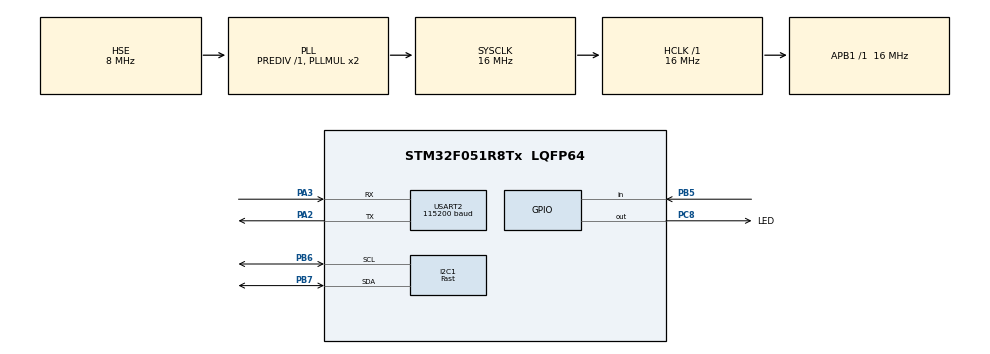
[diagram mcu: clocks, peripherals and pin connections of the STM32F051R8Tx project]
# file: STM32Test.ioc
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I2C1.I2C_Speed_Mode=I2C_Fast
I2C1.Timing=0x0000020B
Mcu.Family=STM32F0
Mcu.Name=STM32F051R8Tx
Mcu.Package=LQFP64
NVIC.I2C1_IRQn=true\:0\:0\:false\:false\:true\:true\:true\:true
NVIC.RCC_IRQn=true\:0\:0\:false\:false\:true\:true\:false\:true
NVIC.TIM1_BRK_UP_TRG_COM_IRQn=true\:0\:0\:false\:false\:true\:true\:true\:true
NVIC.USART2_IRQn=true\:0\:0\:false\:false\:true\:true\:true\:true
PA2.Mode=Asynchronous
PA2.Signal=USART2_TX
PA3.Mode=Asynchronous
PA3.Signal=USART2_RX
PB5.Signal=GPIO_Input
PB6.Mode=I2C
PB6.Signal=I2C1_SCL
PB7.Mode=I2C
PB7.Signal=I2C1_SDA
PC8.GPIO_Label=LED
PC8.Signal=GPIO_Output
PF0-OSC_IN.Mode=HSE-External-Oscillator
PF0-OSC_IN.Signal=RCC_OSC_IN
PF1-OSC_OUT.Mode=HSE-External-Oscillator
PF1-OSC_OUT.Signal=RCC_OSC_OUT
ProjectManager.HeapSize=0x200
ProjectManager.StackSize=0x400
ProjectManager.TargetToolchain=Makefile
RCC.AHBFreq_Value=16000000
RCC.APB1Freq_Value=16000000
RCC.APB1TimFreq_Value=16000000
RCC.HCLKFreq_Value=16000000
RCC.PLLSourceVirtual=RCC_PLLSOURCE_HSE
RCC.SYSCLKFreq_VALUE=16000000
RCC.SYSCLKSource=RCC_SYSCLKSOURCE_PLLCLK
TIM1.Period=25000
TIM1.Prescaler=159
USART2.BaudRate=115200
USART2.VirtualMode-Asynchronous=VM_ASYNC
VP_TIM1_VS_ClockSourceINT.Mode=Internal
board=custom

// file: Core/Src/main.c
/* USER CODE BEGIN Header */
/**
  ******************************************************************************
  * @file           : main.c
  * @brief          : Main program body
  ******************************************************************************
  * @attention
  *
  * Copyright (c) 2024 STMicroelectronics.
  * All rights reserved.
  *
  * This software is licensed under terms that can be found in the LICENSE file
  * in the root directory of this software component.
  * If no LICENSE file comes with this software, it is provided AS-IS.
  *
  ******************************************************************************
  */
/* USER CODE END Header */
#include "main.h"
#include "i2c.h"
#include "tim.h"
#include "usart.h"
#include "gpio.h"

/* USER CODE BEGIN Includes */

#include "MPU6050.h"

/* USER CODE END Includes */

/* USER CODE BEGIN PTD */

int _write(int file, uint8_t* p, int len)
{
	if(HAL_UART_Transmit(&huart2, p, len, len) == HAL_OK )
	{
		return len;
	}
	return 0;
}

/* USER CODE END PTD */

void SystemClock_Config(void);

/* USER CODE BEGIN 0 */

void HAL_TIM_PeriodElapsedCallback(TIM_HandleTypeDef *htim)
{
      //HAL_GPIO_WritePin(LED_GPIO_Port, LED_Pin, GPIO_PIN_SET);
      MPU6050_ProcessData(&MPU6050);
      printf("acc_x_raw: %d, acc_y_raw: %d, acc_z_raw: %d, gyro_x_raw: %d, gyro_y_raw: %d, gyro_z_raw: %d \n\r", MPU6050.acc_x_raw, MPU6050.acc_y_raw, MPU6050.acc_z_raw,MPU6050.gyro_x_raw, MPU6050.gyro_y_raw, MPU6050.gyro_z_raw );

}

/* USER CODE END 0 */

int main(void)
{

  /* MCU Configuration--------------------------------------------------------*/

  /* Reset of all peripherals, Initializes the Flash interface and the Systick. */
  HAL_Init();

  /* Configure the system clock */
  SystemClock_Config();

  /* Initialize all configured peripherals */
  MX_GPIO_Init();
  MX_I2C1_Init();
  MX_USART2_UART_Init();
  MX_TIM1_Init();
  /* USER CODE BEGIN 2 */
  MPU6050_Initialization();

  HAL_TIM_Base_Start_IT(&htim1);

  /* USER CODE END 2 */

  /* Infinite loop */
  while (1)
  {

  }
}

void SystemClock_Config(void)
{
  RCC_OscInitTypeDef RCC_OscInitStruct = {0};
  RCC_ClkInitTypeDef RCC_ClkInitStruct = {0};
  RCC_PeriphCLKInitTypeDef PeriphClkInit = {0};

  /** Initializes the RCC Oscillators according to the specified parameters
  * in the RCC_OscInitTypeDef structure.
  */
  RCC_OscInitStruct.OscillatorType = RCC_OSCILLATORTYPE_HSI|RCC_OSCILLATORTYPE_HSE;
  RCC_OscInitStruct.HSEState = RCC_HSE_ON;
  RCC_OscInitStruct.HSIState = RCC_HSI_ON;
  RCC_OscInitStruct.HSICalibrationValue = RCC_HSICALIBRATION_DEFAULT;
  RCC_OscInitStruct.PLL.PLLState = RCC_PLL_ON;
  RCC_OscInitStruct.PLL.PLLSource = RCC_PLLSOURCE_HSE;
  RCC_OscInitStruct.PLL.PLLMUL = RCC_PLL_MUL2;
  RCC_OscInitStruct.PLL.PREDIV = RCC_PREDIV_DIV1;
  if (HAL_RCC_OscConfig(&RCC_OscInitStruct) != HAL_OK)
  {
    Error_Handler();
  }

  /** Initializes the CPU, AHB and APB buses clocks
  */
  RCC_ClkInitStruct.ClockType = RCC_CLOCKTYPE_HCLK|RCC_CLOCKTYPE_SYSCLK
                              |RCC_CLOCKTYPE_PCLK1;
  RCC_ClkInitStruct.SYSCLKSource = RCC_SYSCLKSOURCE_PLLCLK;
  RCC_ClkInitStruct.AHBCLKDivider = RCC_SYSCLK_DIV1;
  RCC_ClkInitStruct.APB1CLKDivider = RCC_HCLK_DIV1;

  if (HAL_RCC_ClockConfig(&RCC_ClkInitStruct, FLASH_LATENCY_0) != HAL_OK)
  {
    Error_Handler();
  }
  PeriphClkInit.PeriphClockSelection = RCC_PERIPHCLK_I2C1;
  PeriphClkInit.I2c1ClockSelection = RCC_I2C1CLKSOURCE_HSI;
  if (HAL_RCCEx_PeriphCLKConfig(&PeriphClkInit) != HAL_OK)
  {
    Error_Handler();
  }
}

void Error_Handler(void)
{
  __disable_irq();
  while (1)
  {
  }
}
